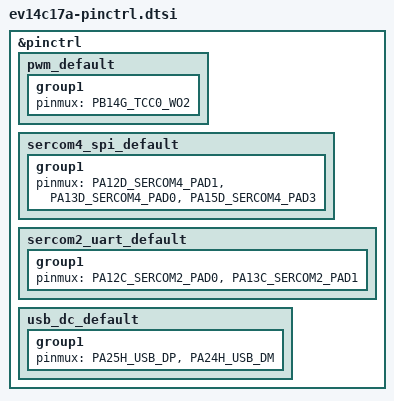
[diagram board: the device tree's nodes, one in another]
/*
 * Copyright (c) 2022, Gerson Fernando Budke <nandojve@gmail.com>
 * SPDX-License-Identifier: Apache-2.0
 */

#include <dt-bindings/pinctrl/same51j-pinctrl.h>

&pinctrl {
	
	pwm_default: pwm_default {
		group1 {
			pinmux = <PB14G_TCC0_WO2>;
		};
	};

	sercom4_spi_default: sercom4_spi_default {
		group1 {
			pinmux = <PA12D_SERCOM4_PAD1>,
				 <PA13D_SERCOM4_PAD0>,
				 <PA15D_SERCOM4_PAD3>;
		};
	};

	sercom2_uart_default: sercom2_uart_default {
		group1 {
			pinmux = <PA12C_SERCOM2_PAD0>,
				 <PA13C_SERCOM2_PAD1>;
		};
	};

	usb_dc_default: usb_dc_default {
		group1 {
			pinmux = <PA25H_USB_DP>,
				 <PA24H_USB_DM>;
		};
	};
};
